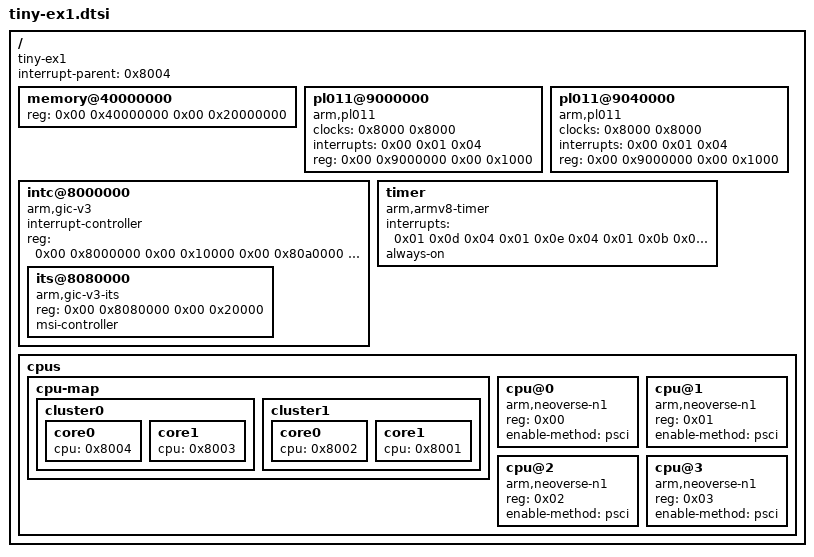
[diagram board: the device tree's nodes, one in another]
/dts-v1/;

/ {
	#size-cells = <0x02>;
	#address-cells = <0x02>;
	interrupt-parent = <0x8004>;
	compatible = "tiny-ex1";

	memory@40000000 {
		reg = <0x00 0x40000000 0x00 0x20000000>;
		device_type = "memory";
	};

	pl011@9000000 {
		clock-names = "uartclk", "apb_pclk";
		clocks = <0x8000 0x8000>;
		interrupts = <0x00 0x01 0x04>;
		reg = <0x00 0x9000000 0x00 0x1000>;
		compatible = "arm,pl011", "arm,primecell";
	};

	pl011@9040000 {
		clock-names = "uartclk", "apb_pclk";
		clocks = <0x8000 0x8000>;
		interrupts = <0x00 0x01 0x04>;
		reg = <0x00 0x9000000 0x00 0x1000>;
		compatible = "arm,pl011", "arm,primecell";
	};

	intc@8000000 {
		compatible = "arm,gic-v3";
		#interrupt-cells = <0x03>;
		#address-cells = <0x02>;
		#size-cells = <0x02>;
		ranges;
		interrupt-controller;
		reg = <0x00 0x8000000 0x00 0x10000 0x00 0x80a0000 0x00 0xf60000>;

		its@8080000 {
			phandle = <0x8008>;
			reg = <0x00 0x8080000 0x00 0x20000>;
			#msi-cells = <0x01>;
			msi-controller;
			compatible = "arm,gic-v3-its";
		};
	};

	timer {
		interrupts = <0x01 0x0d 0x04 0x01 0x0e 0x04 0x01 0x0b 0x04 0x01 0x0a 0x04>;
		always-on;
		compatible = "arm,armv8-timer", "arm,armv7-timer";
	};

	cpus {
		#size-cells = <0x00>;
		#address-cells = <0x01>;

		cpu-map {

			cluster0 {

				core0 {
					cpu = <0x8004>;
				};

				core1 {
					cpu = <0x8003>;
				};
			};

			cluster1 {

				core0 {
					cpu = <0x8002>;
				};

				core1 {
					cpu = <0x8001>;
				};
			};
		};

		cpu@0 {
			phandle = <0x8004>;
			reg = <0x00>;
			enable-method = "psci";
			compatible = "arm,neoverse-n1";
			device_type = "cpu";
		};

		cpu@1 {
			phandle = <0x8003>;
			reg = <0x01>;
			enable-method = "psci";
			compatible = "arm,neoverse-n1";
			device_type = "cpu";
		};

		cpu@2 {
			phandle = <0x8002>;
			reg = <0x02>;
			enable-method = "psci";
			compatible = "arm,neoverse-n1";
			device_type = "cpu";
		};

		cpu@3 {
			phandle = <0x8001>;
			reg = <0x03>;
			enable-method = "psci";
			compatible = "arm,neoverse-n1";
			device_type = "cpu";
		};
	};
};
